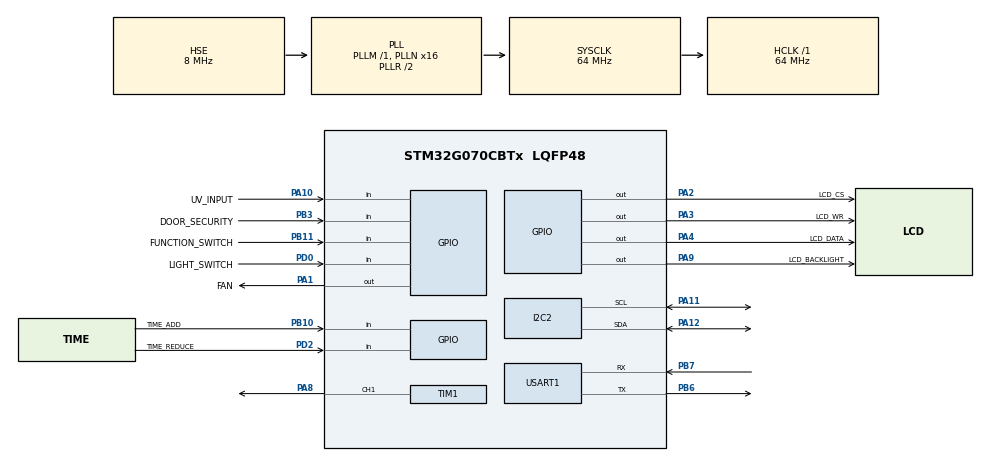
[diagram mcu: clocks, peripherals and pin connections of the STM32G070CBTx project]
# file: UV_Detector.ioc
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I2C2.Timing=0x10B17DB5
Mcu.Family=STM32G0
Mcu.Name=STM32G070CBTx
Mcu.Package=LQFP48
PA1.GPIO_Label=FAN
PA1.PinState=GPIO_PIN_SET
PA1.Signal=GPIO_Output
PA10.GPIO_Label=UV_INPUT
PA10.Signal=GPIO_Input
PA11\ [PA9].GPIO_PuPd=GPIO_PULLUP
PA11\ [PA9].Mode=I2C
PA11\ [PA9].Signal=I2C2_SCL
PA12\ [PA10].GPIO_PuPd=GPIO_PULLUP
PA12\ [PA10].Mode=I2C
PA12\ [PA10].Signal=I2C2_SDA
PA13.Mode=Serial_Wire
PA13.Signal=SYS_SWDIO
PA14-BOOT0.Mode=Serial_Wire
PA14-BOOT0.Signal=SYS_SWCLK
PA2.GPIO_Label=LCD_CS
PA2.GPIO_Speed=GPIO_SPEED_FREQ_VERY_HIGH
PA2.Signal=GPIO_Output
PA3.GPIO_Label=LCD_WR
PA3.GPIO_Speed=GPIO_SPEED_FREQ_VERY_HIGH
PA3.Signal=GPIO_Output
PA4.GPIO_Label=LCD_DATA
PA4.GPIO_Speed=GPIO_SPEED_FREQ_VERY_HIGH
PA4.Signal=GPIO_Output
PA8.Signal=S_TIM1_CH1
PA9.GPIO_Label=LCD_BACKLIGHT
PA9.Signal=GPIO_Output
PB10.GPIO_Label=TIME_ADD
PB10.GPIO_PuPd=GPIO_PULLUP
PB10.Signal=GPIO_Input
PB11.GPIO_Label=FUNCTION_SWITCH
PB11.GPIO_PuPd=GPIO_PULLUP
PB11.Signal=GPIO_Input
PB3.GPIO_Label=DOOR_SECURITY
PB3.GPIO_PuPd=GPIO_NOPULL
PB3.Signal=GPIO_Input
PB6.Mode=Asynchronous
PB6.Signal=USART1_TX
PB7.Mode=Asynchronous
PB7.Signal=USART1_RX
PC14-OSC32_IN\ (PC14).Mode=LSE-External-Oscillator
PC14-OSC32_IN\ (PC14).Signal=RCC_OSC32_IN
PC15-OSC32_OUT\ (PC15).Mode=LSE-External-Oscillator
PC15-OSC32_OUT\ (PC15).Signal=RCC_OSC32_OUT
PD0.GPIO_Label=LIGHT_SWITCH
PD0.GPIO_PuPd=GPIO_PULLUP
PD0.Signal=GPIO_Input
PD2.GPIO_Label=TIME_REDUCE
PD2.GPIO_PuPd=GPIO_PULLUP
PD2.Signal=GPIO_Input
PF0-OSC_IN\ (PF0).Mode=HSE-External-Oscillator
PF0-OSC_IN\ (PF0).Signal=RCC_OSC_IN
PF1-OSC_OUT\ (PF1).Mode=HSE-External-Oscillator
PF1-OSC_OUT\ (PF1).Signal=RCC_OSC_OUT
ProjectManager.HeapSize=0x200
ProjectManager.StackSize=0x400
ProjectManager.TargetToolchain=CMake
RCC.ADCFreq_Value=64000000
RCC.AHBFreq_Value=64000000
RCC.CortexFreq_Value=64000000
RCC.EXTERNAL_CLOCK_VALUE=48000
RCC.HCLKFreq_Value=64000000
RCC.HSE_VALUE=8000000
RCC.HSI_VALUE=16000000
RCC.PLLN=16
RCC.PLLSourceVirtual=RCC_PLLSOURCE_HSE
RCC.SYSCLKFreq_VALUE=64000000
RCC.SYSCLKSource=RCC_SYSCLKSOURCE_PLLCLK
RCC.VCOOutputFreq_Value=128000000
SH.S_TIM1_CH1.0=TIM1_CH1,PWM Generation1 CH1
TIM1.Channel-PWM\ Generation1\ CH1=TIM_CHANNEL_1
USART1.VirtualMode-Asynchronous=VM_ASYNC
board=custom

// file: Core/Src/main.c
/* USER CODE BEGIN Header */
/**
 ******************************************************************************
 * @file           : main.c
 * @brief          : Main program body
 ******************************************************************************
 * @attention
 *
 * Copyright (c) 2026 STMicroelectronics.
 * All rights reserved.
 *
 * This software is licensed under terms that can be found in the LICENSE file
 * in the root directory of this software component.
 * If no LICENSE file comes with this software, it is provided AS-IS.
 *
 ******************************************************************************
 */
/* USER CODE END Header */
#include "main.h"
#include "i2c.h"
#include "tim.h"
#include "usart.h"
#include "gpio.h"

/* USER CODE BEGIN Includes */
#include <stdio.h>

#include "uv_app.h"

/* USER CODE END Includes */

void SystemClock_Config(void);

int main(void)
{

  /* MCU Configuration--------------------------------------------------------*/

  /* Reset of all peripherals, Initializes the Flash interface and the Systick. */
  HAL_Init();

  /* Configure the system clock */
  SystemClock_Config();

  /* Initialize all configured peripherals */
  MX_GPIO_Init();
  MX_I2C2_Init();
  MX_TIM1_Init();
  MX_USART1_UART_Init();
  /* USER CODE BEGIN 2 */
  printf("\r\n[UV] Booting UV_Detector\r\n");
  printf("[UV] HAL, clock, GPIO, I2C2, TIM1 and USART1 initialized\r\n");
  printf("[UV] USART1 debug console ready: 115200 8N1\r\n");
  printf("[UV] UV_App_Init begin\r\n");

  UV_App_Init();

  printf("[UV] UV_App_Init done\r\n");
  printf("[UV] Enter main loop\r\n");

  /* USER CODE END 2 */

  /* Infinite loop */
  while (1)
  {

    /* USER CODE BEGIN 3 */
    UV_App_Task();
  }
  /* USER CODE END 3 */
}

void SystemClock_Config(void)
{
  RCC_OscInitTypeDef RCC_OscInitStruct = {0};
  RCC_ClkInitTypeDef RCC_ClkInitStruct = {0};

  /** Configure the main internal regulator output voltage
  */
  HAL_PWREx_ControlVoltageScaling(PWR_REGULATOR_VOLTAGE_SCALE1);

  /** Initializes the RCC Oscillators according to the specified parameters
  * in the RCC_OscInitTypeDef structure.
  */
  RCC_OscInitStruct.OscillatorType = RCC_OSCILLATORTYPE_HSE;
  RCC_OscInitStruct.HSEState = RCC_HSE_ON;
  RCC_OscInitStruct.PLL.PLLState = RCC_PLL_ON;
  RCC_OscInitStruct.PLL.PLLSource = RCC_PLLSOURCE_HSE;
  RCC_OscInitStruct.PLL.PLLM = RCC_PLLM_DIV1;
  RCC_OscInitStruct.PLL.PLLN = 16;
  RCC_OscInitStruct.PLL.PLLP = RCC_PLLP_DIV2;
  RCC_OscInitStruct.PLL.PLLR = RCC_PLLR_DIV2;
  if (HAL_RCC_OscConfig(&RCC_OscInitStruct) != HAL_OK)
  {
    Error_Handler();
  }

  /** Initializes the CPU, AHB and APB buses clocks
  */
  RCC_ClkInitStruct.ClockType = RCC_CLOCKTYPE_HCLK|RCC_CLOCKTYPE_SYSCLK
                              |RCC_CLOCKTYPE_PCLK1;
  RCC_ClkInitStruct.SYSCLKSource = RCC_SYSCLKSOURCE_PLLCLK;
  RCC_ClkInitStruct.AHBCLKDivider = RCC_SYSCLK_DIV1;
  RCC_ClkInitStruct.APB1CLKDivider = RCC_HCLK_DIV1;

  if (HAL_RCC_ClockConfig(&RCC_ClkInitStruct, FLASH_LATENCY_2) != HAL_OK)
  {
    Error_Handler();
  }
}

void Error_Handler(void)
{
  __disable_irq();
  while (1)
  {
  }
}
